# CC2340R5 register map
File version: 1.0
CPU: CM0P 1.0, other endian, MPU, FPU, 3 interrupt priority bits
Registers are 32-bit, read-write, reset 0x0 unless marked. A register's access mark holds for its fields unless they carry their own. Offsets are from the block's base; [hi:lo] are bit positions; {n}, {i} and the like mark numbered series; 'fields as' and 'values as' point back to an identical list.

## LRFDDBELL
Base 0x40080000
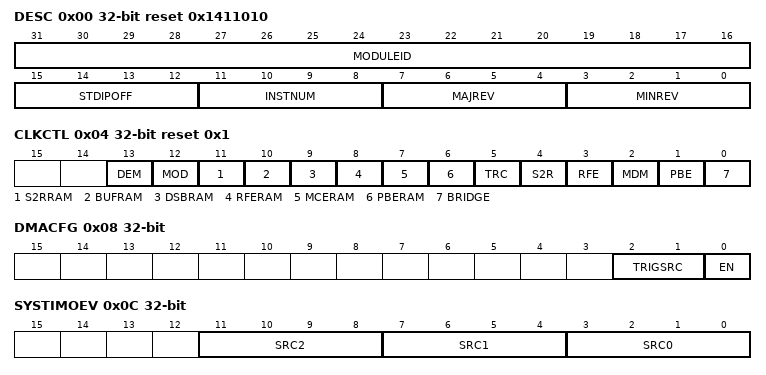
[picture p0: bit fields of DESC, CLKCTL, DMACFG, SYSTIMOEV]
0x00 DESC reset 0x1411010 — This register identifies the peripheral and its exact version.
  [31:16] MODULEID — [31:16] Module identifier used to uniquely identify this IP.
  [15:12] STDIPOFF — [15:12] Standard IP MMR block offset. Standard IP MMRs are the set of from aggregated IRQ registers till DTB.
    1=STDIPMMR (These MMRs begin at offset 64*STDIPOFF from IP base address); 0=NO_STDIPMMR (STDIP MMRs do not exist)
  [11:8] INSTNUM — [11:8] IP Instance Number. If multiple instances of IP exist in the device, this field can identify the instance number
  [7:4] MAJREV — [7:4] Major rev of the IP
  [3:0] MINREV — [3:0] Minor rev of the IP
0x04 CLKCTL reset 0x1 — Controls the functional clock gates for the individual sub-modules. Writing a bit to zero does not necessarily switch off the corresponding clock. It can also be requested internally. A clock will only be switched off if internal and external requests are removed
  [all] fields
    1=EN (Clock is requested); 0=DIS (Clock not requested)
  [13] DEM — [13:13] Enable the clock to the demodulator. The modem will request this clock automatically. This bit is to force the clock to be free running
  [12] MOD — [12:12] Enable the clock to the modulator. Modem will request this clock automatically, this bit is to force the modulator clock to be free running.
  [11] S2RRAM — [11:11] Enable the clock to the S2R RAM
  [10] BUFRAM — [10:10] Enable the clock to the BUFRAM
  [9] DSBRAM — [9:9] Enable the clock to the DSB RAM
  [8] RFERAM — [8:8] Enable the clock to the RFE RAM
  [7] MCERAM — [7:7] Enable the clock to the MCE RAM
  [6] PBERAM — [6:6] Enable the clock to the PBE RAM
  [5] TRC — [5:5] Enable the clock to the Tracer
  [4] S2R — [4:4] Enable the clock to Samples2RAM
  [3] RFE — [3:3] Enable the clock to the RFE
  [2] MDM — [2:2] Enable the clock to the Modem
  [1] PBE — [1:1] Enable the clock to the PBE
  [0] BRIDGE — [0:0] Clock enable to AHB bridge. The bridge will request it's own clock, this bit it to override that feature to have a free running clock.
0x08 DMACFG — DMA Configuration
  [2:1] TRIGSRC — [2:1] Select DMA trigger source
    3=FIFO (The DMA is triggered from the FIFO. See the FIFO configration register for what FIFO event will generate the trigger); 2=RFEFW (The DMA is triggered by the MCE FW trigger); 1=MCEFW (The DMA is triggered by the MCE FW trigger); 0=PBEFW (The DMA is triggered by the PBE FW trigger)
  [0] EN — [0:0] Enables the DMA interface
    1=ON (Enable DMA interface. The triggers are able to give activity on the interface); 0=OFF (Disable DMA interface, no activity on interface)
0x0C SYSTIMOEV — Systimer Output Event Control Register. Controls routing of internal events to the three systimer output events
  [all] fields
    12=PBESYSTIM2 (PBE FW systimer capture event 2); 11=PBESYSTIM1 (PBE FW systimer capture event 1); 10=PBESYSTIM0 (PBE FW systimer capture event 0); 9=MDMHW2 (MDM HW event 2); 8=MDMHW1 (MDM HW event 1); 7=MDMHW0 (MDM HW event 0); 6=MCESYSTIM2 (MCE FW systimer capture event 2); 5=MCESYSTIM1 (MCE FW systimer capture event 1); 4=MCESYSTIM0 (MCE FW systimer capture event 0); 3=RFESYSTIM2 (RFE FW systimer capture event 2); 2=RFESYSTIM1 (RFE FW systimer capture event 1); 1=RFESYSTIM0 (RFE FW systimer capture event 0); 0=DIS (Output not enabled, always 0.)
  [11:8] SRC2 — [11:8] Select source of systimer output event 2 (capture source)
  [7:4] SRC1 — [7:4] Select source of systimer output event 1 (capture source)
  [3:0] SRC0 — [3:0] Select source of systimer output event 0 (capture source)
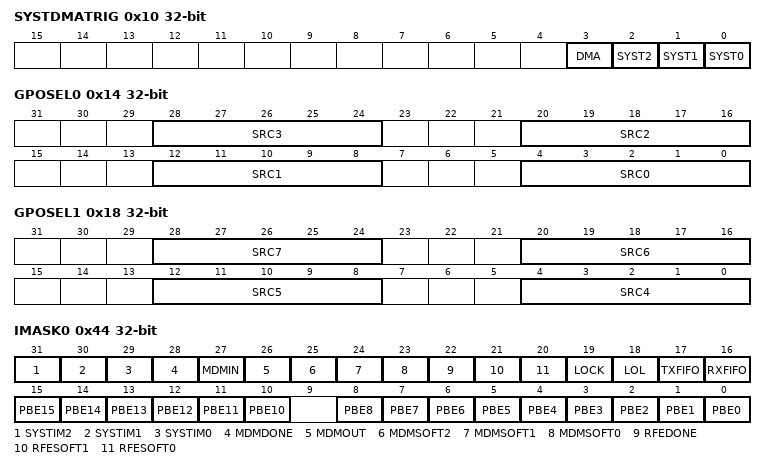
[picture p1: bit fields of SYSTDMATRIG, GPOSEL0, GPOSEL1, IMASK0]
0x10 SYSTDMATRIG — Manual triggering of systimer capture event or DMA trigger This comes on top of any HW driven sources configured in SYSTIMOEV
  [3] DMA wo — [3:3] Trigger a DMA request from the Radio
    1=TRIG (DMA request manually triggered); 0=NOTRIG (DMA not manually triggered)
  [2] SYST2 wo — [2:2] Trigger a capture event on systimer event 0 from the radio
    1=TRIG (Capture event triggered); 0=NOTRIG (Not capture event triggered)
  [1] SYST1 wo — [1:1] Trigger a capture event on systimer event 0 from the radio
    values as SYST2
  [0] SYST0 wo — [0:0] Trigger a capture event on systimer event 0 from the radio
    values as SYST2
0x14 GPOSEL0 — Controls routing of GPO signals from MDM, RFE and PBE to the radio GPO lines
  [8n+4:8n] SRC{n} (n=0..3) — [{8n+4}:{8n}] Select source of radio GPO line {n}
    25=RFCTRC (Select RFCTRC GPO line {n}); {v}=RFEGPO{v-17} (Select RFE GPO line {v-17}) (v=17..24); {v}=MCEGPO{v-9} (Select MCE GPO line {v-9}) (v=9..16); {v}=PBEGPO{v-1} (Select PBE GPO line {v-1}) (v=1..8); 0=DIS (Output not enabled)
0x18 GPOSEL1 — Controls routing of GPO signals from MDM, RFE and PBE to the radio GPO lines
  [28:24] SRC7 — [28:24] Select source of radio GPO line 7
    25=RFCTRC (Select RFCTRC GPO line 7); {v}=RFEGPO{v-17} (Select RFE GPO line {v-17}) (v=17..24); {v}=MCEGPO{v-9} (Select MCE GPO line {v-9}) (v=9..16); {v}=PBEGPO{v-1} (Select PBE GPO line {v-1}) (v=1..8); 0=DIS (No output not enabled)
  [20:16] SRC6 — [20:16] Select source of radio GPO line 6
    25=RFCTRC (Select RFCTRC GPO line 6); {v}=RFEGPO{v-17} (Select RFE GPO line {v-17}) (v=20..24); 19=RFEGPO2 (Selevt RFE GPO line 2); 18=RFEGPO1 (Select RFE GPO line 1); 17=RFEGPO0 (Select RFE GPO line 0); {v}=MCEGPO{v-9} (Select MCE GPO line {v-9}) (v=9..16); {v}=PBEGPO{v-1} (Select PBE GPO line {v-1}) (v=1..8); 0=DIS (No output not enabled)
  [12:8] SRC5 — [12:8] Select source of radio GPO line 5
    25=RFCTRC (Select RFCTRC GPO line 5); {v}=RFEGPO{v-17} (Select RFE GPO line {v-17}) (v=17..24); {v}=MCEGPO{v-9} (Select MCE GPO line {v-9}) (v=9..16); {v}=PBEGPO{v-1} (Select PBE GPO line {v-1}) (v=1..8); 0=DIS (No output not enabled)
  [4:0] SRC4 — [4:0] Select source of radio GPO line 4
    25=RFCTRC (Select RFCTRC GPO line 4); {v}=RFEGPO{v-17} (Select RFE GPO line {v-17}) (v=17..24); {v}=MCEGPO{v-9} (Select MCE GPO line {v-9}) (v=9..16); {v}=PBEGPO{v-1} (Select PBE GPO line {v-1}) (v=1..8); 0=DIS (No output not enabled)
0x44 IMASK0 — Interrupt mask. This register selects interrupt sources which are allowed to pass from RIS to MIS when the corresponding bit-fields are set to 1.
  [all] fields
    1=EN (Enable interrupt mask); 0=DIS (Disable interrupt mask)
  [31] SYSTIM2 — [31:31] SYSTIM2 event
  [30] SYSTIM1 — [30:30] SYSTIM1 event
  [29] SYSTIM0 — [29:29] SYSTIM0 event
  [28] MDMDONE — [28:28] MDMDONE event
  [27] MDMIN — [27:27] MDMIN event
  [26] MDMOUT — [26:26] MDMOUT event
  [25] MDMSOFT2 — [25:25] MDMSOFT2 event
  [24] MDMSOFT1 — [24:24] MDMSOFT2 event
  [23] MDMSOFT0 — [23:23] MDMSOFT2 event
  [22] RFEDONE — [22:22] RFEDONE event
  [21] RFESOFT1 — [21:21] RFESOFT1 event
  [20] RFESOFT0 — [20:20] RFESOFT0 event
  [19] LOCK — [19:19] LOCK event
  [18] LOL — [18:18] LOSS_OF_LOCK event
  [17] TXFIFO — [17:17] TXFIFO event
  [16] RXFIFO — [16:16] RXFIFO event
  [n] PBE{n} (n=10..15) — [{n}:{n}] PBE{n} event
  [n] PBE{n} (n=0..8) — [{n}:{n}] PBE{n} event
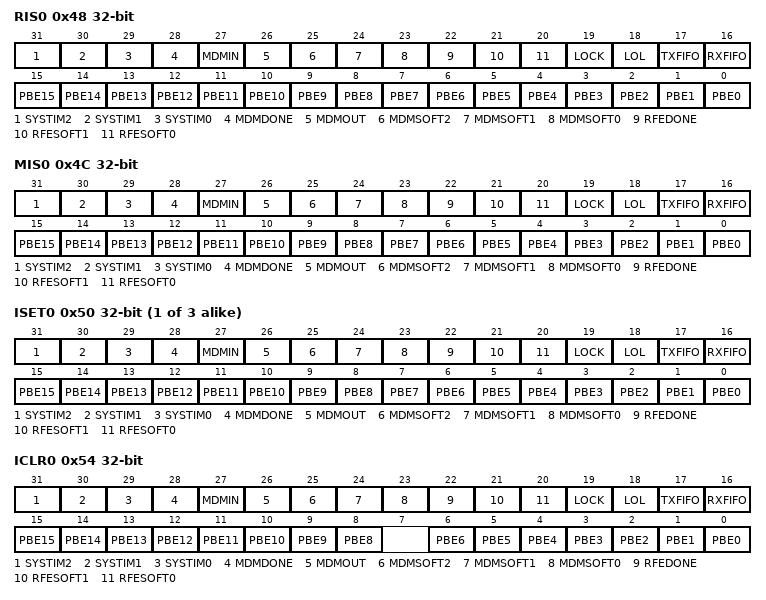
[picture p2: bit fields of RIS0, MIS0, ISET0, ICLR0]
0x48 RIS0 — Raw interrupt status. This register reflects the state of all pending interrupts, regardless of masking. This register allows the user to implement a poll scheme. A flag set in this register can be cleared by writing 1 to the corresponding ICLR register bit.
  [all] fields
    1=SET (Interrupt occurred); 0=CLR (Interrupt did not occur)
  [31] SYSTIM2 ro — [31:31] SYSTIM2 event
  [30] SYSTIM1 ro — [30:30] SYSTIM1 event
  [29] SYSTIM0 ro — [29:29] SYSTIM0 event
  [28] MDMDONE ro — [28:28] MDMDONE event
  [27] MDMIN ro — [27:27] MDMIN event
  [26] MDMOUT ro — [26:26] MDMOUT event
  [25] MDMSOFT2 ro — [25:25] MDMSOFT event
  [24] MDMSOFT1 ro — [24:24] MDMSOFT1 event
  [23] MDMSOFT0 ro — [23:23] MDMSOFT event
  [22] RFEDONE ro — [22:22] RFEDONE event
  [21] RFESOFT1 ro — [21:21] RFESOFT1 event
  [20] RFESOFT0 ro — [20:20] RFESOFT0 event
  [19] LOCK ro — [19:19] LOCK event
  [18] LOL ro — [18:18] LOSS_OF_LOCK event
  [17] TXFIFO ro — [17:17] TXFIFO event
  [16] RXFIFO ro — [16:16] RXFIFO event
  [n] PBE{n} ro (n=0..15) — [{n}:{n}] PBE{n} event
0x4C MIS0 — Masked interrupt status. This register is simply a bitwise AND of the contents of IMASK and RIS.*] registers. A flag set in this register can be cleared by writing 1 to the corresponding ICLR register bit.
  fields as RIS0
{0x50+0x40*i} ISET{i} (i=0..2) — Interrupt set register. This register can used by software for diagnostics and safety checking purposes. Writing a 1 to a bit in this register will set the event and the corresponding RIS bit also gets set. If the corresponding IMASK bit is set, then the corresponding MIS register bit also gets set.
  [all] fields
    1=SET (Set Interrupt); 0=NOEFF (Writing 0 has no effect)
  [31] SYSTIM2 — [31:31] SYSTIM2 event
  [30] SYSTIM1 — [30:30] SYSTIM1 event
  [29] SYSTIM0 — [29:29] SYSTIM0 event
  [28] MDMDONE — [28:28] MDMDONE event
  [27] MDMIN — [27:27] MDMIN event
  [26] MDMOUT — [26:26] MDMOUT event
  [25] MDMSOFT2 — [25:25] MDMSOFT event
  [24] MDMSOFT1 — [24:24] MDMSOFT1 event
  [23] MDMSOFT0 — [23:23] MDMSOFT event
  [22] RFEDONE — [22:22] RFEDONE event
  [21] RFESOFT1 — [21:21] RFESOFT1 event
  [20] RFESOFT0 — [20:20] RFESOFT0 event
  [19] LOCK — [19:19] LOCK event
  [18] LOL — [18:18] LOSS_OF_LOCK event
  [17] TXFIFO — [17:17] TXFIFO event
  [16] RXFIFO — [16:16] RXFIFO event
  [n] PBE{n} (n=0..15) — [{n}:{n}] PBE{n} event
0x54 ICLR0 — Interrupt clear. Write a 1 to clear corresponding Interrupt.
  [all] fields
    1=CLR (Clear Interrupt); 0=NOEFF (Writing 0 has no effect)
  [31] SYSTIM2 — [31:31] SYSTIM2 event
  [30] SYSTIM1 — [30:30] SYSTIM1 event
  [29] SYSTIM0 — [29:29] SYSTIM0 event
  [28] MDMDONE — [28:28] MDMDONE event
  [27] MDMIN — [27:27] MDMIN event
  [26] MDMOUT — [26:26] MDMOUT event
  [25] MDMSOFT2 — [25:25] MDMSOFT event
  [24] MDMSOFT1 — [24:24] MDMSOFT1 event
  [23] MDMSOFT0 — [23:23] MDMSOFT event
  [22] RFEDONE — [22:22] RFEDONE event
  [21] RFESOFT1 — [21:21] RFESOFT1 event
  [20] RFESOFT0 — [20:20] RFESOFT0 event
  [19] LOCK — [19:19] LOCK event
  [18] LOL — [18:18] LOSS_OF_LOCK event
  [17] TXFIFO — [17:17] TXFIFO event
  [16] RXFIFO — [16:16] RXFIFO event
  [n] PBE{n} (n=8..15) — [{n}:{n}] PBE{n} event
  [n] PBE{n} (n=0..6) — [{n}:{n}] PBE{n} event
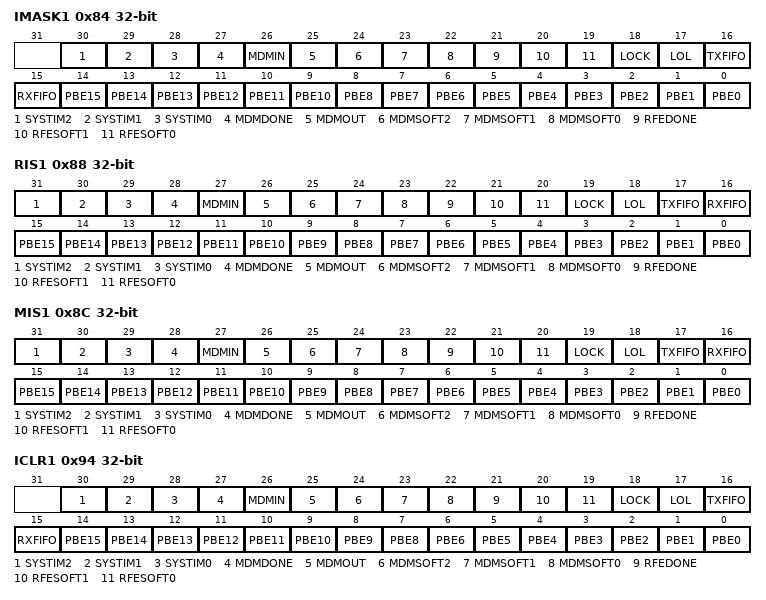
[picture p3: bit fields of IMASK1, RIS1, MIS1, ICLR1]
0x84 IMASK1 — Interrupt mask. This register selects interrupt sources which are allowed to pass from RIS to MIS when the corresponding bit-fields are set to 1.
  [all] fields
    1=EN (Enable interrupt mask); 0=DIS (Disable interrupt mask)
  [30] SYSTIM2 — [30:30] SYSTIM2 event
  [29] SYSTIM1 — [29:29] SYSTIM1 event
  [28] SYSTIM0 — [28:28] SYSTIM0 event
  [27] MDMDONE — [27:27] MDMDONE event
  [26] MDMIN — [26:26] MDMIN event
  [25] MDMOUT — [25:25] MDMOUT event
  [24] MDMSOFT2 — [24:24] MDMSOFT2 event
  [23] MDMSOFT1 — [23:23] MDMSOFT2 event
  [22] MDMSOFT0 — [22:22] MDMSOFT2 event
  [21] RFEDONE — [21:21] RFEDONE event
  [20] RFESOFT1 — [20:20] RFESOFT1 event
  [19] RFESOFT0 — [19:19] RFESOFT0 event
  [18] LOCK — [18:18] LOCK event
  [17] LOL — [17:17] LOSS_OF_LOCK event
  [16] TXFIFO — [16:16] TXFIFO event
  [15] RXFIFO — [15:15] RXFIFO event
  [n-1] PBE{n} (n=10..15) — [{n-1}:{n-1}] PBE{n} event
  [n] PBE{n} (n=0..8) — [{n}:{n}] PBE{n} event
0x88 RIS1 — Raw interrupt status. Reflects all pending interrupts, regardless of masking. The RIS0 register allows the user to implement a poll scheme. A flag set in this register can be cleared by writing 1 to the ICLR register bit even if the corresponding IMASK bit is not enabled.
  fields as RIS0
0x8C MIS1 — Masked interrupt status. This is an AND of the IMASK and RIS registers.
  fields as RIS0
0x94 ICLR1 — Interrupt clear. Write a 1 to clear corresponding Interrupt.
  [all] fields
    1=CLR (Clear Interrupt); 0=NOEFF (Writing 0 has no effect)
  [30] SYSTIM2 — [30:30] SYSTIM2 event
  [29] SYSTIM1 — [29:29] SYSTIM1 event
  [28] SYSTIM0 — [28:28] SYSTIM0 event
  [27] MDMDONE — [27:27] MDMDONE event
  [26] MDMIN — [26:26] MDMIN event
  [25] MDMOUT — [25:25] MDMOUT event
  [24] MDMSOFT2 — [24:24] MDMSOFT event
  [23] MDMSOFT1 — [23:23] MDMSOFT1 event
  [22] MDMSOFT0 — [22:22] MDMSOFT event
  [21] RFEDONE — [21:21] RFEDONE event
  [20] RFESOFT1 — [20:20] RFESOFT1 event
  [19] RFESOFT0 — [19:19] RFESOFT0 event
  [18] LOCK — [18:18] LOCK event
  [17] LOL — [17:17] LOSS_OF_LOCK event
  [16] TXFIFO — [16:16] TXFIFO event
  [15] RXFIFO — [15:15] RXFIFO event
  [n-1] PBE{n} (n=8..15) — [{n-1}:{n-1}] PBE{n} event
  [n] PBE{n} (n=0..6) — [{n}:{n}] PBE{n} event
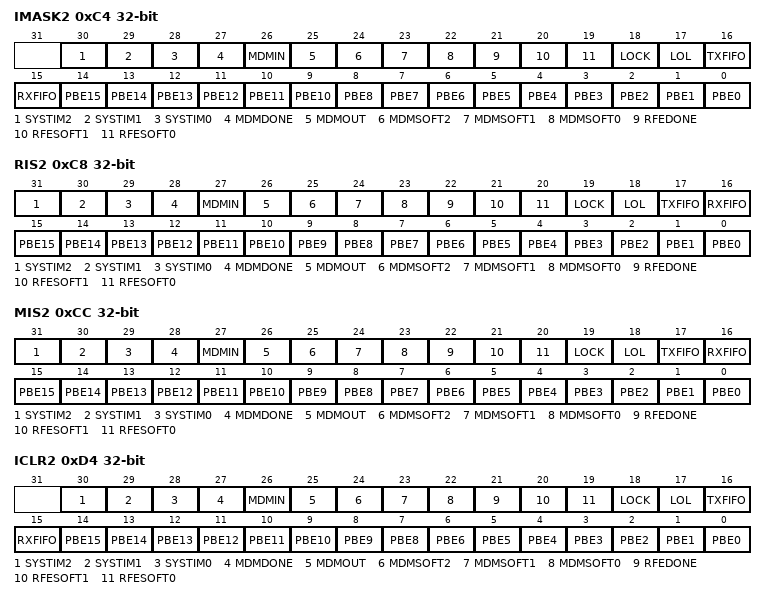
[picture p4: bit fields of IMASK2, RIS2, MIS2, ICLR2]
0xC4 IMASK2 — Interrupt mask. This register selects interrupt sources which are allowed to pass from RIS to MIS when the corresponding bit-fields are set to 1.
  fields as IMASK1
0xC8 RIS2 — Raw interrupt status. Reflects all pending interrupts, regardless of masking. The RIS0 register allows the user to implement a poll scheme. A flag set in this register can be cleared by writing 1 to the ICLR register bit even if the corresponding IMASK bit is not enabled.
  fields as RIS0
0xCC MIS2 — Masked interrupt status. This is an AND of the IMASK and RIS registers.
  fields as RIS0
0xD4 ICLR2 — Interrupt clear. Write a 1 to clear corresponding Interrupt.
  fields as ICLR1
